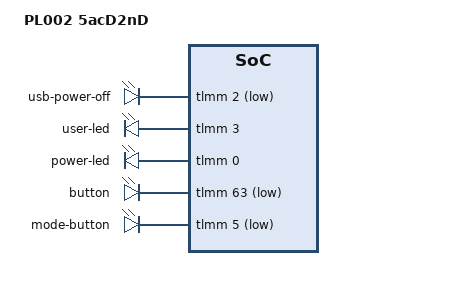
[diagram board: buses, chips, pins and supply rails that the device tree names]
/dts-v1/;
#include "ipq40xx.dtsi"

/ {
	model = "PL002 5acD2nD";

	leds {
		compatible = "leds-rb";
		usb-power-off {
			gpios = <&tlmm 2 GPIO_ACTIVE_LOW>;
		};
		user-led {
			gpios = <&tlmm 3 GPIO_ACTIVE_HIGH>;
		};
		power-led {
			gpios = <&tlmm 0 GPIO_ACTIVE_HIGH>;
			default-state = "keep";
		};
		button {
			gpios = <&tlmm 63 GPIO_ACTIVE_LOW>;
			default-state = "input";
		};
		mode-button {
			gpios = <&tlmm 5 GPIO_ACTIVE_LOW>;
			default-state = "input";
		};
	};
};

&edma {
	port_map = <3 4(-1)>;
};
